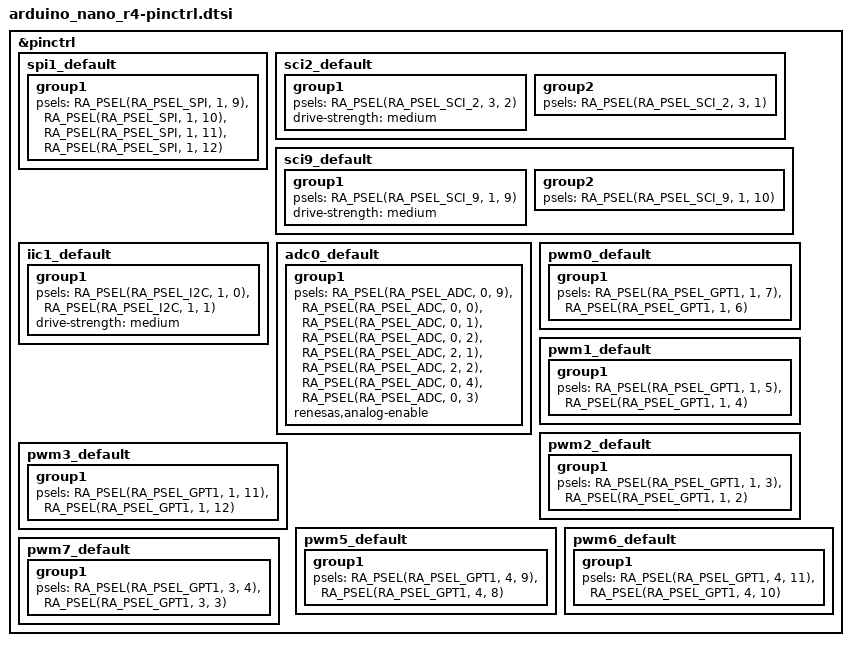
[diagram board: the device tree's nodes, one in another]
/*
 * Copyright (c) 2026 Sahaj Sarup
 *
 * SPDX-License-Identifier: Apache-2.0
 */

&pinctrl {
	spi1_default: spi1_default {
		group1 {
			/* MOSI MISO RSPCK SSL */
			psels = <RA_PSEL(RA_PSEL_SPI, 1, 9)>,
				<RA_PSEL(RA_PSEL_SPI, 1, 10)>,
				<RA_PSEL(RA_PSEL_SPI, 1, 11)>,
				<RA_PSEL(RA_PSEL_SPI, 1, 12)>;
		};
	};

	sci2_default: sci2_default {
		group1 {
			/* tx */
			psels = <RA_PSEL(RA_PSEL_SCI_2, 3, 2)>;
			drive-strength = "medium";
		};

		group2 {
			/* rx */
			psels = <RA_PSEL(RA_PSEL_SCI_2, 3, 1)>;
		};
	};

	sci9_default: sci9_default {
		group1 {
			/* tx */
			psels = <RA_PSEL(RA_PSEL_SCI_9, 1, 9)>;
			drive-strength = "medium";
		};

		group2 {
			/* rx */
			psels = <RA_PSEL(RA_PSEL_SCI_9, 1, 10)>;
		};
	};

	iic1_default: iic1_default {
		group1 {
			/* SCL1 SDA1 */
			psels = <RA_PSEL(RA_PSEL_I2C, 1, 0)>,
				<RA_PSEL(RA_PSEL_I2C, 1, 1)>;
			drive-strength = "medium";
		};
	};

	adc0_default: adc0_default {
		group1 {
			/* input */
			psels = <RA_PSEL(RA_PSEL_ADC, 0, 9)>,
				<RA_PSEL(RA_PSEL_ADC, 0, 0)>,
				<RA_PSEL(RA_PSEL_ADC, 0, 1)>,
				<RA_PSEL(RA_PSEL_ADC, 0, 2)>,
				<RA_PSEL(RA_PSEL_ADC, 2, 1)>,
				<RA_PSEL(RA_PSEL_ADC, 2, 2)>,
				<RA_PSEL(RA_PSEL_ADC, 0, 4)>,
				<RA_PSEL(RA_PSEL_ADC, 0, 3)>;
			renesas,analog-enable;
		};
	};

	pwm0_default: pwm0_default {
		group1 {
			/* GTIOC0A GTIOC0B */
			psels = <RA_PSEL(RA_PSEL_GPT1, 1, 7)>,
				<RA_PSEL(RA_PSEL_GPT1, 1, 6)>;
		};
	};

	pwm1_default: pwm1_default {
		group1 {
			/* GTIOC1A GTIOC1B */
			psels = <RA_PSEL(RA_PSEL_GPT1, 1, 5)>,
				<RA_PSEL(RA_PSEL_GPT1, 1, 4)>;
		};
	};

	pwm2_default: pwm2_default {
		group1 {
			/* GTIOC2A GTIOC2B */
			psels = <RA_PSEL(RA_PSEL_GPT1, 1, 3)>,
				<RA_PSEL(RA_PSEL_GPT1, 1, 2)>;
		};
	};

	pwm3_default: pwm3_default {
		group1 {
			/* GTIOC3A GTIOC3B */
			psels = <RA_PSEL(RA_PSEL_GPT1, 1, 11)>,
				<RA_PSEL(RA_PSEL_GPT1, 1, 12)>;
		};
	};

	pwm5_default: pwm5_default {
		group1 {
			/* GTIOC5A GTIOC5B */
			psels = <RA_PSEL(RA_PSEL_GPT1, 4, 9)>,
				<RA_PSEL(RA_PSEL_GPT1, 4, 8)>;
		};
	};

	pwm6_default: pwm6_default {
		group1 {
			/* GTIOC6A GTIOC6B */
			psels = <RA_PSEL(RA_PSEL_GPT1, 4, 11)>,
				<RA_PSEL(RA_PSEL_GPT1, 4, 10)>;
		};
	};

	pwm7_default: pwm7_default {
		group1 {
			/* GTIOC7A GTIOC7B */
			psels = <RA_PSEL(RA_PSEL_GPT1, 3, 4)>,
				<RA_PSEL(RA_PSEL_GPT1, 3, 3)>;
		};
	};
};
